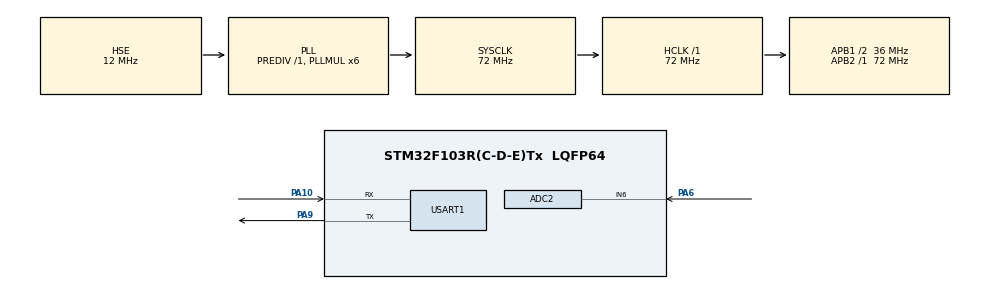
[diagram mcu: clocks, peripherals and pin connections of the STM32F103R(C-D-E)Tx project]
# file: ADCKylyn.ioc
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ADC2.Channel-17\#ChannelRegularConversion=ADC_CHANNEL_6
ADC2.NbrOfConversionFlag=1
ADC2.Rank-17\#ChannelRegularConversion=1
ADC2.SamplingTime-17\#ChannelRegularConversion=ADC_SAMPLETIME_1CYCLE_5
Mcu.Family=STM32F1
Mcu.Name=STM32F103R(C-D-E)Tx
Mcu.Package=LQFP64
NVIC.PriorityGroup=NVIC_PRIORITYGROUP_4
PA10.Mode=Asynchronous
PA10.Signal=USART1_RX
PA13.Mode=Serial_Wire
PA13.Signal=SYS_JTMS-SWDIO
PA14.Mode=Serial_Wire
PA14.Signal=SYS_JTCK-SWCLK
PA6.Signal=ADCx_IN6
PA9.Mode=Asynchronous
PA9.Signal=USART1_TX
PD0-OSC_IN.Mode=HSE-External-Oscillator
PD0-OSC_IN.Signal=RCC_OSC_IN
PD1-OSC_OUT.Mode=HSE-External-Oscillator
PD1-OSC_OUT.Signal=RCC_OSC_OUT
ProjectManager.HeapSize=0x200
ProjectManager.StackSize=0x400
ProjectManager.TargetToolchain=SW4STM32
RCC.ADCPresc=RCC_ADCPCLK2_DIV6
RCC.AHBFreq_Value=72000000
RCC.APB1CLKDivider=RCC_HCLK_DIV2
RCC.APB1Freq_Value=36000000
RCC.APB1TimFreq_Value=72000000
RCC.APB2Freq_Value=72000000
RCC.APB2TimFreq_Value=72000000
RCC.HCLKFreq_Value=72000000
RCC.HSE_VALUE=12000000
RCC.PLLMUL=RCC_PLL_MUL6
RCC.PLLSourceVirtual=RCC_PLLSOURCE_HSE
RCC.SYSCLKFreq_VALUE=72000000
RCC.SYSCLKSource=RCC_SYSCLKSOURCE_PLLCLK
RCC.USBFreq_Value=72000000
SH.ADCx_IN6.0=ADC2_IN6,IN6
USART1.VirtualMode=VM_ASYNC
board=ADCKylyn

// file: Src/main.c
/**
  ******************************************************************************
  * @file           : main.c
  * @brief          : Main program body
  ******************************************************************************
  ** This notice applies to any and all portions of this file
  * that are not between comment pairs USER CODE BEGIN and
  * USER CODE END. Other portions of this file, whether
  * inserted by the user or by software development tools
  * are owned by their respective copyright owners.
  *
  * COPYRIGHT(c) 2018 STMicroelectronics
  *
  * Redistribution and use in source and binary forms, with or without modification,
  * are permitted provided that the following conditions are met:
  *   1. Redistributions of source code must retain the above copyright notice,
  *      this list of conditions and the following disclaimer.
  *   2. Redistributions in binary form must reproduce the above copyright notice,
  *      this list of conditions and the following disclaimer in the documentation
  *      and/or other materials provided with the distribution.
  *   3. Neither the name of STMicroelectronics nor the names of its contributors
  *      may be used to endorse or promote products derived from this software
  *      without specific prior written permission.
  *
  * THIS SOFTWARE IS PROVIDED BY THE COPYRIGHT HOLDERS AND CONTRIBUTORS "AS IS"
  * AND ANY EXPRESS OR IMPLIED WARRANTIES, INCLUDING, BUT NOT LIMITED TO, THE
  * IMPLIED WARRANTIES OF MERCHANTABILITY AND FITNESS FOR A PARTICULAR PURPOSE ARE
  * DISCLAIMED. IN NO EVENT SHALL THE COPYRIGHT HOLDER OR CONTRIBUTORS BE LIABLE
  * FOR ANY DIRECT, INDIRECT, INCIDENTAL, SPECIAL, EXEMPLARY, OR CONSEQUENTIAL
  * DAMAGES (INCLUDING, BUT NOT LIMITED TO, PROCUREMENT OF SUBSTITUTE GOODS OR
  * SERVICES; LOSS OF USE, DATA, OR PROFITS; OR BUSINESS INTERRUPTION) HOWEVER
  * CAUSED AND ON ANY THEORY OF LIABILITY, WHETHER IN CONTRACT, STRICT LIABILITY,
  * OR TORT (INCLUDING NEGLIGENCE OR OTHERWISE) ARISING IN ANY WAY OUT OF THE USE
  * OF THIS SOFTWARE, EVEN IF ADVISED OF THE POSSIBILITY OF SUCH DAMAGE.
  *
  ******************************************************************************
  */
#include "main.h"
#include "stm32f1xx_hal.h"
#include "adc.h"
#include "usart.h"
#include "gpio.h"

/* USER CODE BEGIN PV */
/* Private variables ---------------------------------------------------------*/

/* USER CODE END PV */

void SystemClock_Config(void);

/* USER CODE BEGIN PFP */
/* Private function prototypes -----------------------------------------------*/
#ifdef __GNUC__
#define PUTCHAR_PROTOTYPE int __io_putchar(int ch)
#else
#define PUTCHAR_PROTOTYPE int fputc(int ch, FILE *f)
#endif

/* USER CODE END PFP */

/* USER CODE BEGIN 0 */
PUTCHAR_PROTOTYPE
{
    HAL_UART_Transmit(&huart1 , (uint8_t *)&ch, 1, 0xFFFF);
    return ch;
}
/* USER CODE END 0 */

int main(void)
{
  /* USER CODE BEGIN 1 */

	uint16_t ADC2_Value;
  /* USER CODE END 1 */

  /* MCU Configuration----------------------------------------------------------*/

  /* Reset of all peripherals, Initializes the Flash interface and the Systick. */
  HAL_Init();

  /* Configure the system clock */
  SystemClock_Config();

  /* Initialize all configured peripherals */
  MX_GPIO_Init();
  MX_USART1_UART_Init();
  MX_ADC2_Init();

  /* Infinite loop */
  while (1)
  {

  /* USER CODE BEGIN 3 */
//      HAL_ADC_Start(&hadc1);
//      HAL_ADC_PollForConversion(&hadc1, 50);
//
//      if(HAL_IS_BIT_SET(HAL_ADC_GetState(&hadc1), HAL_ADC_STATE_REG_EOC))
//      {
//          ADC1_Value = HAL_ADC_GetValue(&hadc1);
//          /* 温度计算公式  (V25-Vsense)/Avg_Slope+25 , Avg_Slope = 4.3 , V25 = 1.43,
//           * Avg_Slope单位是mV/C，所以V25和Vsense需要转换为mV*/
//          printf("===========\r\n");
//          printf("ADC1_Value:%d \r\n",ADC1_Value);
//          /*printf打印浮点数去除警告信息The float formatting support (-u _printf_float) is not enabled from linker flags
//            (project properties > C/C++ Build > Settings > Tool Settings (TAB) > MCU GCC Linker > Miscellaneous > Linker flags),
//if you are using nanolib “-specs=nano.specs” you need to add “-u _printf_float” to enable float printf.*/
//          printf("MCU Temperature : %.1fC \r\n",((1430 - ADC1_Value*3300/4096)/4.3 + 25 ));
//      }
//      HAL_ADC_Start(&hadc1);
//      HAL_ADC_PollForConversion(&hadc1, 50);
//
//      if(HAL_IS_BIT_SET(HAL_ADC_GetState(&hadc1), HAL_ADC_STATE_REG_EOC))
//      {
//          ADC1_Value = HAL_ADC_GetValue(&hadc1);
//          printf("ADC1 reading %d \r\n",ADC1_Value);
//          printf("PA6 Voltage : %.4f \r\n",ADC1_Value*3.3f/4096);
//          printf("\r\n");
//      }

      HAL_ADC_Start(&hadc2);
      HAL_ADC_PollForConversion(&hadc2, 50);

      if(HAL_IS_BIT_SET(HAL_ADC_GetState(&hadc2), HAL_ADC_STATE_REG_EOC))
      {
          ADC2_Value = HAL_ADC_GetValue(&hadc2);
          printf("ADC2 Reading : %d \r\n",ADC2_Value);
          printf("PA6 Voltage : %.4f \r\n",ADC2_Value*3.3f/4096);
          printf("\r\n");
      }

      HAL_Delay(1000);
  }
  /* USER CODE END 3 */

}

void SystemClock_Config(void)
{

  RCC_OscInitTypeDef RCC_OscInitStruct;
  RCC_ClkInitTypeDef RCC_ClkInitStruct;
  RCC_PeriphCLKInitTypeDef PeriphClkInit;

    /**Initializes the CPU, AHB and APB busses clocks
    */
  RCC_OscInitStruct.OscillatorType = RCC_OSCILLATORTYPE_HSE;
  RCC_OscInitStruct.HSEState = RCC_HSE_ON;
  RCC_OscInitStruct.HSEPredivValue = RCC_HSE_PREDIV_DIV1;
  RCC_OscInitStruct.HSIState = RCC_HSI_ON;
  RCC_OscInitStruct.PLL.PLLState = RCC_PLL_ON;
  RCC_OscInitStruct.PLL.PLLSource = RCC_PLLSOURCE_HSE;
  RCC_OscInitStruct.PLL.PLLMUL = RCC_PLL_MUL6;
  if (HAL_RCC_OscConfig(&RCC_OscInitStruct) != HAL_OK)
  {
    _Error_Handler(__FILE__, __LINE__);
  }

    /**Initializes the CPU, AHB and APB busses clocks
    */
  RCC_ClkInitStruct.ClockType = RCC_CLOCKTYPE_HCLK|RCC_CLOCKTYPE_SYSCLK
                              |RCC_CLOCKTYPE_PCLK1|RCC_CLOCKTYPE_PCLK2;
  RCC_ClkInitStruct.SYSCLKSource = RCC_SYSCLKSOURCE_PLLCLK;
  RCC_ClkInitStruct.AHBCLKDivider = RCC_SYSCLK_DIV1;
  RCC_ClkInitStruct.APB1CLKDivider = RCC_HCLK_DIV2;
  RCC_ClkInitStruct.APB2CLKDivider = RCC_HCLK_DIV1;

  if (HAL_RCC_ClockConfig(&RCC_ClkInitStruct, FLASH_LATENCY_2) != HAL_OK)
  {
    _Error_Handler(__FILE__, __LINE__);
  }

  PeriphClkInit.PeriphClockSelection = RCC_PERIPHCLK_ADC;
  PeriphClkInit.AdcClockSelection = RCC_ADCPCLK2_DIV6;
  if (HAL_RCCEx_PeriphCLKConfig(&PeriphClkInit) != HAL_OK)
  {
    _Error_Handler(__FILE__, __LINE__);
  }

    /**Configure the Systick interrupt time
    */
  HAL_SYSTICK_Config(HAL_RCC_GetHCLKFreq()/1000);

    /**Configure the Systick
    */
  HAL_SYSTICK_CLKSourceConfig(SYSTICK_CLKSOURCE_HCLK);

  /* SysTick_IRQn interrupt configuration */
  HAL_NVIC_SetPriority(SysTick_IRQn, 0, 0);
}

void _Error_Handler(char *file, int line)
{
  while(1)
  {
  }
}

/************************ (C) COPYRIGHT STMicroelectronics *****END OF FILE****/
